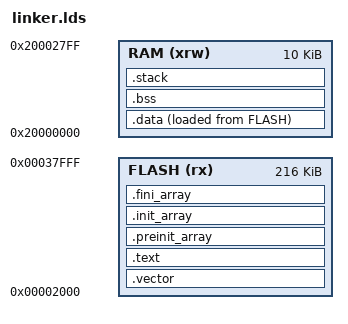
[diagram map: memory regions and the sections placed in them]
ENTRY( _start )

__stack_size = 512;
PROVIDE( _stack_size = __stack_size );

MEMORY
{
    /* CH32V20x_D6 -> 10 KB SRAM */
    /* allow full flash (incl. non-zero-wait) */
    FLASH (rx) : ORIGIN = 0x00002000, LENGTH = (224K - 8K)
    RAM (xrw) : ORIGIN = 0x20000000, LENGTH = 10K
}

SECTIONS
{
    .vector :
    {
        *(.vector);
        . = ALIGN(4);
    } >FLASH
    
    .text :
    {
        *(.text)
        *(.text.*)
        *(.rodata)
        *(.rodata*)
        *(.gnu.linkonce.t.*)
        . = ALIGN(4);
    } >FLASH

    .preinit_array :
    {
        PROVIDE_HIDDEN (__preinit_array_start = .);
        KEEP (*(.preinit_array))
        PROVIDE_HIDDEN (__preinit_array_end = .);
    } >FLASH

    .init_array :
    {
        PROVIDE_HIDDEN (__init_array_start = .);
        KEEP (*(SORT_BY_INIT_PRIORITY(.init_array.*) SORT_BY_INIT_PRIORITY(.ctors.*)))
        KEEP (*(.init_array EXCLUDE_FILE (*crtbegin.o *crtbegin?.o *crtend.o *crtend?.o ) .ctors))
        PROVIDE_HIDDEN (__init_array_end = .);
    } >FLASH

    .fini_array :
    {
        PROVIDE_HIDDEN (__fini_array_start = .);
        KEEP (*(SORT_BY_INIT_PRIORITY(.fini_array.*) SORT_BY_INIT_PRIORITY(.dtors.*)))
        KEEP (*(.fini_array EXCLUDE_FILE (*crtbegin.o *crtbegin?.o *crtend.o *crtend?.o ) .dtors))
        PROVIDE_HIDDEN (__fini_array_end = .);
    } >FLASH

    PROVIDE(_data_lma = .);

    .data :
    {
        PROVIDE(_data_vma = .);
        *(.gnu.linkonce.r.*)
        *(.data .data.*)
        *(.gnu.linkonce.d.*)
        . = ALIGN(4);
        PROVIDE( __global_pointer$ = . + 0x800 );
        *(.sdata .sdata.*)
        *(.sdata2.*)
        *(.gnu.linkonce.s.*)
        . = ALIGN(4);
        *(.srodata.cst16)
        *(.srodata.cst8)
        *(.srodata.cst4)
        *(.srodata.cst2)
        *(.srodata .srodata.*)
        . = ALIGN(4);
        PROVIDE( _edata = .);
    } >RAM AT>FLASH

    .bss :
    {
        PROVIDE( _sbss = .);
        *(.sbss*)
        *(.gnu.linkonce.sb.*)
        *(.bss*)
        *(.gnu.linkonce.b.*)
        *(COMMON*)
        . = ALIGN(4);
        PROVIDE( _ebss = .);
    } >RAM

    PROVIDE( _end = _ebss);

    .stack ORIGIN(RAM) + LENGTH(RAM) - __stack_size :
    {
        PROVIDE( _heap_end = . );
        PROVIDE( _susrstack = . );
        . = . + __stack_size;
        PROVIDE( _eusrstack = .);
    } >RAM 
}
